# MB9BF21xT register map
File version: 1.7
CPU: 
Registers are 32-bit, read-write, reset 0x0 unless marked. A register's access mark holds for its fields unless they carry their own. Offsets are from the block's base; [hi:lo] are bit positions; {n}, {i} and the like mark numbered series; 'fields as' and 'values as' point back to an identical list.

## SBSSR — Software-based Simultaneous Startup Register
Base 0x40025F00
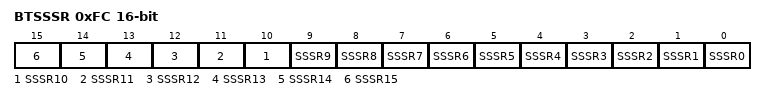
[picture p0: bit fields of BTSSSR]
0xFC BTSSSR 16-bit wo reset not defined — Software-based Simultaneous Startup Register
  [n] SSSR{n} (n=0..15) — Bit{n} of BTSSSR

## BT0 — Base Timer 0
Base 0x40025000
Same registers: BT1 0x40025040, BT2 0x40025080, BT3 0x400250C0, BT4 0x40025200, BT5 0x40025240, BT6 0x40025280, BT7 0x400252C0, BT8 0x40025400, BT9 0x40025440, BT10 0x40025480, BT11 0x400254C0, BT12 0x40025600, BT13 0x40025640, BT14 0x40025680, BT15 0x400256C0
0x00 PWM_PCSR 16-bit reset not defined (PWM view) — PWM Cycle Set Register
0x00 PPG_PRLL 16-bit reset not defined (PPG view) — LOW Width Reload Register
0x00 RT_PCSR 16-bit reset not defined (RT view) — PWM Cycle Set Register
0x04 PWM_PDUT 16-bit reset not defined (PWM view) — PWM Duty Set Register
0x04 PPG_PRLH 16-bit reset not defined (PPG view) — HIGH Width Reload Register
0x04 PWC_DTBF 16-bit ro (PWC view) — Data Buffer Register
0x08 PWM_TMR 16-bit ro (PWM view) — Timer Register
0x08 PPG_TMR 16-bit ro (PPG view) — Timer Register
0x08 RT_TMR 16-bit ro reset not defined (RT view) — Timer Register
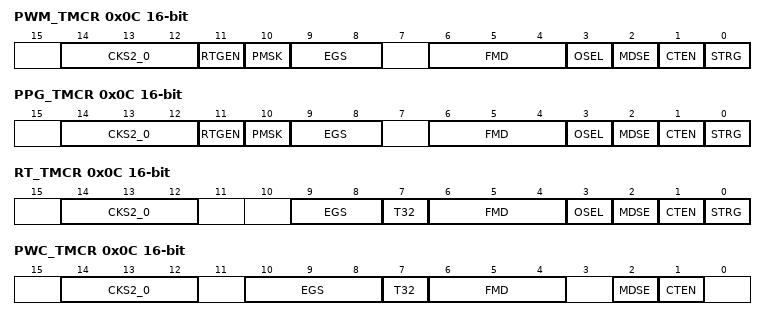
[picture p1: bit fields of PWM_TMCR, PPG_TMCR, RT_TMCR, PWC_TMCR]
0x0C PWM_TMCR 16-bit (PWM view) — Timer Control Register
  [14:12] CKS2_0 — Count clock selection bit
  [11] RTGEN — Restart enable bit
  [10] PMSK — Pulse output mask bit
  [9:8] EGS — Trigger input edge selection bits
  [6:4] FMD — Timer function selection bits
  [3] OSEL — Output polarity specification bit
  [2] MDSE — Mode selection bit
  [1] CTEN — Count operation enable bit
  [0] STRG — Software trigger bit
0x0C PPG_TMCR 16-bit (PPG view) — Timer Control Register
  fields as PWM_TMCR
0x0C RT_TMCR 16-bit (RT view) — Timer Control Register
  [14:12] CKS2_0 — Count clock selection bit
  [9:8] EGS — Trigger input edge selection bits
  [7] T32 — 32-bit timer selection bit
  [6:4] FMD — Timer function selection bits
  [3] OSEL — Output polarity specification bit
  [2] MDSE — Mode selection bit
  [1] CTEN — Timer enable bit
  [0] STRG — Software trigger bit
0x0C PWC_TMCR 16-bit (PWC view) — Timer Control Register
  [14:12] CKS2_0 — Count clock selection bit
  [10:8] EGS — Measurement edge selection bits
  [7] T32 — 32-bit timer selection bit
  [6:4] FMD — Timer function selection bits
  [2] MDSE — Mode selection bit
  [1] CTEN — Timer enable bit
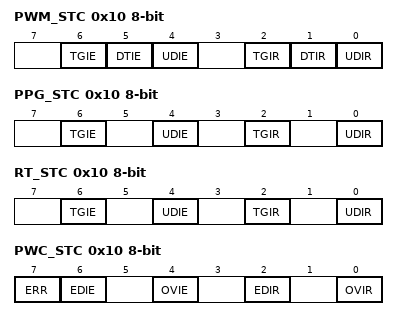
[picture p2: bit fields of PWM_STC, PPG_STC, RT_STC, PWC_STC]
0x10 PWM_STC 8-bit (PWM view) — Status Control Register
  [6] TGIE — Trigger interrupt request enable bit
  [5] DTIE — Duty match interrupt request enable bit
  [4] UDIE — Underflow interrupt request enable bit
  [2] TGIR — Trigger interrupt request bit
  [1] DTIR — Duty match interrupt request bit
  [0] UDIR — Underflow interrupt request bit
0x10 PPG_STC 8-bit (PPG view) — Status Control Register
  [6] TGIE — Trigger interrupt request enable bit
  [4] UDIE — Underflow interrupt request enable bit
  [2] TGIR — Trigger interrupt request bit
  [0] UDIR — Underflow interrupt request bit
0x10 RT_STC 8-bit (RT view) — Status Control Register
  fields as PPG_STC
0x10 PWC_STC 8-bit (PWC view) — Status Control Register
  [7] ERR ro — Error flag bit
  [6] EDIE — Measurement completion interrupt request enable bit
  [4] OVIE — Overflow interrupt request enable bit
  [2] EDIR ro — Measurement completion interrupt request bit
  [0] OVIR — Overflow interrupt request bit
0x11 PWM_TMCR2 8-bit (PWM view) — Timer Control Register 2
  [0] CKS3 — Count clock selection bit
0x11 PPG_TMCR2 8-bit (reset mask 0x1) (PPG view) — Timer Control Register 2
  [1] CKS3 — Count clock selection bit
0x11 RT_TMCR2 8-bit (RT view) — Timer Control Register 2
  [0] CKS3 — Count clock selection bit
0x11 PWC_TMCR2 8-bit (PWC view) — Timer Control Register 2
  [0] CKS3 — Count clock selection bit

## QPRC0 — Quadrature Position/Revolution Counter 0
Base 0x40026000
Same registers: QPRC1 0x40026040, QPRC2 0x40026080
0x00 QPCR 16-bit — QPRC Position Count Register
0x04 QRCR 16-bit — QPRC Revolution Count Register
0x08 QPCCR 16-bit — QPRC Position Counter Compare Register
0x0C QPRCR 16-bit — QPRC Position and Revolution Counter Compare Register
0x10 QMPR 16-bit reset 0xFFFF — QPRC Maximum Position Register
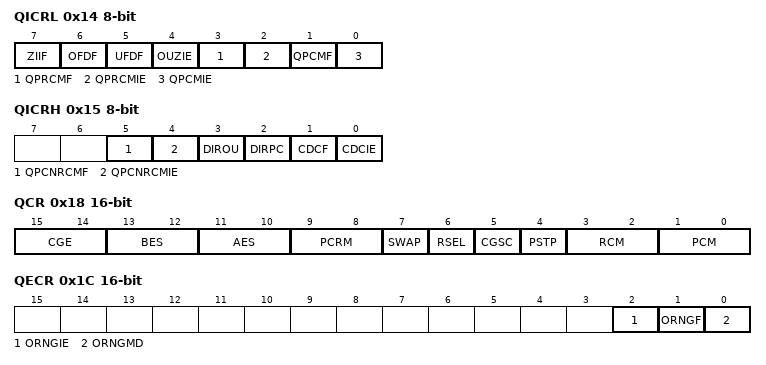
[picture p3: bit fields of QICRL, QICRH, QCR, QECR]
0x14 QICRL 8-bit — Low-Order Bytes of QPRC Interrupt Control Register
  [7] ZIIF — Zero index interrupt request flag bit
  [6] OFDF — Overflow interrupt request flag bit
  [5] UFDF — Underflow interrupt request flag bit
  [4] OUZIE — "Overflow, underflow, or zero index interrupt enable bit"
  [3] QPRCMF — PC and RC match interrupt request flag bit
  [2] QPRCMIE — PC and RC match interrupt enable bit
  [1] QPCMF — PC match interrupt request flag bit
  [0] QPCMIE — PC match interrupt enable bit
0x15 QICRH 8-bit — High-Order Bytes of QPRC Interrupt Control Register
  [5] QPCNRCMF — PC match and RC match interrupt request flag bit
  [4] QPCNRCMIE — PC match and RC match interrupt enable bit
  [3] DIROU ro — Last position counter flow direction bit
  [2] DIRPC ro — Last position counter direction bit
  [1] CDCF — Count inversion interrupt request flag bit
  [0] CDCIE — Count inversion interrupt enable bit
0x18 QCR 16-bit — QPRC Control Register
  [15:14] CGE — Detection edge selection bits
  [13:12] BES — BIN detection edge selection bits
  [11:10] AES — AIN detection edge selection bits
  [9:8] PCRM — Position counter reset mask bits
  [7] SWAP — Swap bit
  [6] RSEL — Register function selection bit
  [5] CGSC — Count clear or gate selection bit
  [4] PSTP — Position counter stop bit
  [3:2] RCM — Revolution counter mode bits
  [1:0] PCM — Position counter mode bits
0x1C QECR 16-bit — QPRC Extension Control Register
  [2] ORNGIE — Outrange interrupt enable bit
  [1] ORNGF — Outrange interrupt request flag bit
  [0] ORNGMD — Outrange mode selection bit
0x3C QRCRR 16-bit — Quad counter rotation count Register
0x3E QPCRR 16-bit — Quad counter position count Register
